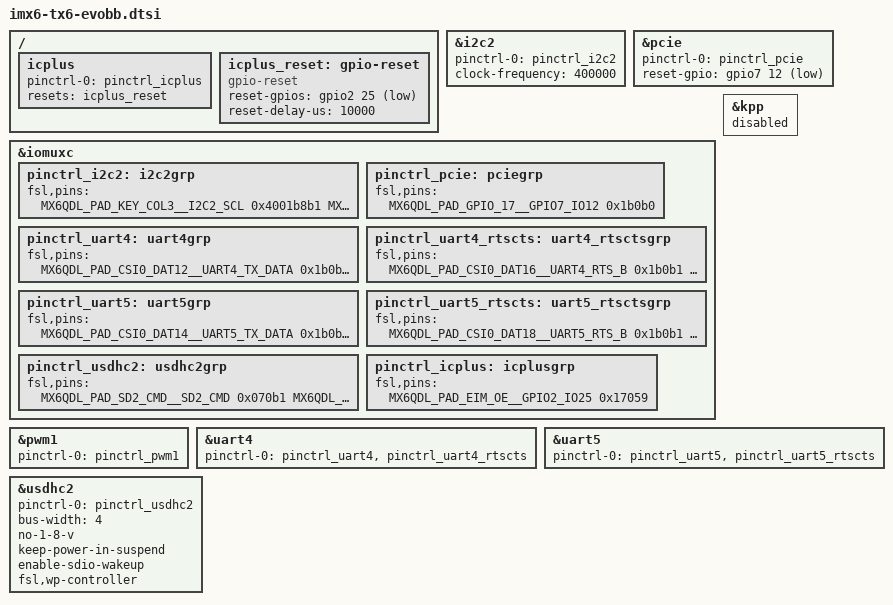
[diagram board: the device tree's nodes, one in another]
/*
 * Copyright 2014-2016 Lothar Waßmann <LW@KARO-electronics.de>
 *
 * This file is dual-licensed: you can use it either under the terms
 * of the GPL or the X11 license, at your option. Note that this dual
 * licensing only applies to this file, and not this project as a
 * whole.
 *
 *  a) This file is free software; you can redistribute it and/or
 *     modify it under the terms of the GNU General Public License
 *     version 2 as published by the Free Software Foundation.
 *
 *     This file is distributed in the hope that it will be useful,
 *     but WITHOUT ANY WARRANTY; without even the implied warranty of
 *     MERCHANTABILITY or FITNESS FOR A PARTICULAR PURPOSE.  See the
 *     GNU General Public License for more details.
 *
 * Or, alternatively,
 *
 *  b) Permission is hereby granted, free of charge, to any person
 *     obtaining a copy of this software and associated documentation
 *     files (the "Software"), to deal in the Software without
 *     restriction, including without limitation the rights to use,
 *     copy, modify, merge, publish, distribute, sublicense, and/or
 *     sell copies of the Software, and to permit persons to whom the
 *     Software is furnished to do so, subject to the following
 *     conditions:
 *
 *     The above copyright notice and this permission notice shall be
 *     included in all copies or substantial portions of the Software.
 *
 *     THE SOFTWARE IS PROVIDED "AS IS", WITHOUT WARRANTY OF ANY KIND,
 *     EXPRESS OR IMPLIED, INCLUDING BUT NOT LIMITED TO THE WARRANTIES
 *     OF MERCHANTABILITY, FITNESS FOR A PARTICULAR PURPOSE AND
 *     NONINFRINGEMENT. IN NO EVENT SHALL THE AUTHORS OR COPYRIGHT
 *     HOLDERS BE LIABLE FOR ANY CLAIM, DAMAGES OR OTHER LIABILITY,
 *     WHETHER IN AN ACTION OF CONTRACT, TORT OR OTHERWISE, ARISING
 *     FROM, OUT OF OR IN CONNECTION WITH THE SOFTWARE OR THE USE OR
 *     OTHER DEALINGS IN THE SOFTWARE.
 */

/ {
	icplus {
		pinctrl-names = "default";
		pinctrl-0 = <&pinctrl_icplus>;
		resets = <&icplus_reset>;
		reset-names = "reset";
		status = "okay";
	};


	icplus_reset: gpio-reset {
		compatible = "gpio-reset";
		reset-gpios = <&gpio2 25 GPIO_ACTIVE_LOW>;
		reset-delay-us = <10000>;
		#reset-cells = <0>;
	};
};

&i2c2 {
        pinctrl-names = "default";
        pinctrl-0 = <&pinctrl_i2c2>;
        clock-frequency = <400000>;
        status = "okay";
};

&pcie {
	pinctrl-names = "default";
	pinctrl-0 = <&pinctrl_pcie>;
	reset-gpio = <&gpio7 12 GPIO_ACTIVE_LOW>;
	status = "okay";
};


&iomuxc {
	pinctrl-names = "default";

	pinctrl_i2c2: i2c2grp {
                fsl,pins = <
			MX6QDL_PAD_KEY_COL3__I2C2_SCL           0x4001b8b1
			MX6QDL_PAD_KEY_ROW3__I2C2_SDA           0x4001b8b1
		>;
	};

	pinctrl_pcie: pciegrp {
		fsl,pins = <
			MX6QDL_PAD_GPIO_17__GPIO7_IO12		0x1b0b0
		>;
	};

        pinctrl_uart4: uart4grp {
                fsl,pins = <
                        MX6QDL_PAD_CSI0_DAT12__UART4_TX_DATA    0x1b0b1
                        MX6QDL_PAD_CSI0_DAT13__UART4_RX_DATA    0x1b0b1
                >;
        };

        pinctrl_uart4_rtscts: uart4_rtsctsgrp {
                fsl,pins = <
                        MX6QDL_PAD_CSI0_DAT16__UART4_RTS_B      0x1b0b1
                        MX6QDL_PAD_CSI0_DAT17__UART4_CTS_B      0x1b0b1
                >;
        };


        pinctrl_uart5: uart5grp {
                fsl,pins = <
                        MX6QDL_PAD_CSI0_DAT14__UART5_TX_DATA    0x1b0b1
                        MX6QDL_PAD_CSI0_DAT15__UART5_RX_DATA    0x1b0b1
                >;
        };

        pinctrl_uart5_rtscts: uart5_rtsctsgrp {
                fsl,pins = <
                        MX6QDL_PAD_CSI0_DAT18__UART5_RTS_B      0x1b0b1
                        MX6QDL_PAD_CSI0_DAT19__UART5_CTS_B      0x1b0b1
                >;
        };

	pinctrl_usdhc2: usdhc2grp {
		fsl,pins = <
			MX6QDL_PAD_SD2_CMD__SD2_CMD		0x070b1
			MX6QDL_PAD_SD2_CLK__SD2_CLK		0x070b1
			MX6QDL_PAD_SD2_DAT0__SD2_DATA0		0x070b1
			MX6QDL_PAD_SD2_DAT1__SD2_DATA1		0x070b1
			MX6QDL_PAD_SD2_DAT2__SD2_DATA2		0x070b1
			MX6QDL_PAD_SD2_DAT3__SD2_DATA3		0x030b1 /* SD2 DAT3/CD */
		>;
	};

	pinctrl_icplus: icplusgrp {
		fsl,pins = <
			MX6QDL_PAD_EIM_OE__GPIO2_IO25		0x17059
		>;
	};

};

&kpp {
	status = "disabled";
};

&pwm1 {
	pinctrl-names = "default";
	pinctrl-0 = <&pinctrl_pwm1>;
	#pwm-cells = <3>;
	status = "okay";
};

&uart4 {
        pinctrl-names = "default";
        pinctrl-0 = <&pinctrl_uart4 &pinctrl_uart4_rtscts>;
        status = "okay";
};

&uart5 {
        pinctrl-names = "default";
        pinctrl-0 = <&pinctrl_uart5 &pinctrl_uart5_rtscts>;
        status = "okay";
};

&usdhc2 {
	pinctrl-names = "default";
	pinctrl-0 = <&pinctrl_usdhc2>;
	bus-width = <4>;
	no-1-8-v;
	/delete-property/ cd-gpios;
	keep-power-in-suspend;
	enable-sdio-wakeup;
	fsl,wp-controller;
	status = "okay";
};
